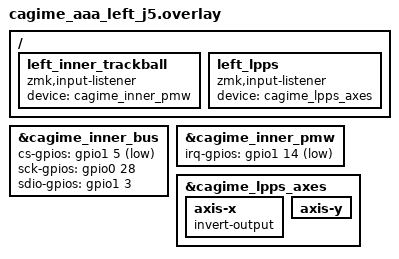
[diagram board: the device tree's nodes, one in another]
/* Add to cagime_aaa_left only on boards with the J5 routing correction. */
#include "cagime_inner_pmw3610.dtsi"

#define CAGIME_LPPS_PSELS <NRF_PSEL(SPIM_SCK, 1, 3)>, \
                         <NRF_PSEL(SPIM_MOSI, 1, 5)>, \
                         <NRF_PSEL(SPIM_MISO, 0, 28)>
#include "cagime_lpps.dtsi"

#define CAGIME_INNER_ENCODER_A <&gpio1 5 (GPIO_ACTIVE_HIGH | GPIO_PULL_UP)>
#define CAGIME_INNER_ENCODER_B <&gpio0 28 (GPIO_ACTIVE_HIGH | GPIO_PULL_UP)>
#define CAGIME_INNER_KEY_GPIO <&gpio1 5 (GPIO_ACTIVE_LOW | GPIO_PULL_UP)>
#include "cagime_inner_gpio.dtsi"

/* J5 pads 1 through 4: XIAO footprint pads 22, 3, 10 and 21. */
&cagime_inner_bus {
    cs-gpios = <&gpio1 5 GPIO_ACTIVE_LOW>;
    sck-gpios = <&gpio0 28 GPIO_ACTIVE_HIGH>;
    sdio-gpios = <&gpio1 3 GPIO_ACTIVE_HIGH>;
};

&cagime_inner_pmw {
    irq-gpios = <&gpio1 14 (GPIO_ACTIVE_LOW | GPIO_PULL_UP)>;
};

&cagime_lpps_axes {
    axis-x { invert-output; };
    axis-y { /delete-property/ invert-output; };
};

/ {
    left_inner_trackball {
        compatible = "zmk,input-listener";
        device = <&cagime_inner_pmw>;
    };

    left_lpps {
        compatible = "zmk,input-listener";
        device = <&cagime_lpps_axes>;
    };
};
